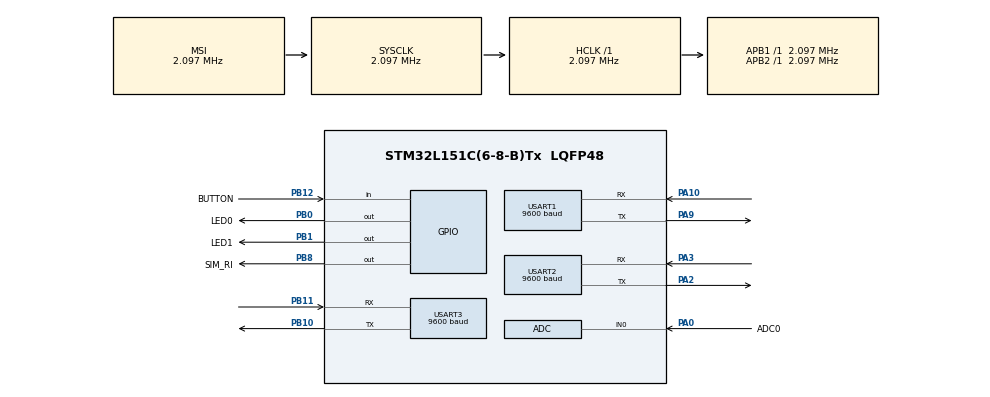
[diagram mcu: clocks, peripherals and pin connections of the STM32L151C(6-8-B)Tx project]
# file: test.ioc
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ADC.Channel-0\#ChannelRegularConversion=ADC_CHANNEL_0
ADC.NbrOfConversionFlag=1
ADC.Rank-0\#ChannelRegularConversion=1
ADC.SamplingTime-0\#ChannelRegularConversion=ADC_SAMPLETIME_4CYCLES
Mcu.Family=STM32L1
Mcu.Name=STM32L151C(6-8-B)Tx
Mcu.Package=LQFP48
NVIC.PriorityGroup=NVIC_PRIORITYGROUP_4
PA0-WKUP1.GPIO_Label=ADC0
PA0-WKUP1.Mode=IN0
PA0-WKUP1.Signal=ADC_IN0
PA10.Mode=Asynchronous
PA10.Signal=USART1_RX
PA13.Mode=Serial_Wire
PA13.Signal=SYS_JTMS-SWDIO
PA14.Mode=Serial_Wire
PA14.Signal=SYS_JTCK-SWCLK
PA2.Mode=Asynchronous
PA2.Signal=USART2_TX
PA3.Mode=Asynchronous
PA3.Signal=USART2_RX
PA9.Mode=Asynchronous
PA9.Signal=USART1_TX
PB0.GPIO_Label=LED0
PB0.Signal=GPIO_Output
PB1.GPIO_Label=LED1
PB1.Signal=GPIO_Output
PB10.Mode=Asynchronous
PB10.Signal=USART3_TX
PB11.Mode=Asynchronous
PB11.Signal=USART3_RX
PB12.GPIO_Label=BUTTON
PB12.GPIO_PuPd=GPIO_PULLUP
PB12.Signal=GPIO_Input
PB8.GPIO_Label=SIM_RI
PB8.Signal=GPIO_Output
ProjectManager.HeapSize=0x200
ProjectManager.StackSize=0x400
ProjectManager.TargetToolchain=MDK-ARM V5.32
RCC.AHBFreq_Value=2097000
RCC.APB1Freq_Value=2097000
RCC.APB1TimFreq_Value=2097000
RCC.APB2Freq_Value=2097000
RCC.APB2TimFreq_Value=2097000
RCC.HCLKFreq_Value=2097000
RCC.HSE_VALUE=24000000
RCC.HSI_VALUE=16000000
RCC.LSE_VALUE=32768
RCC.MSI_VALUE=2097000
RCC.SYSCLKFreq_VALUE=2097000
RCC.VCOOutputFreq_Value=48000000
USART1.BaudRate=9600
USART1.VirtualMode=VM_ASYNC
USART2.BaudRate=9600
USART2.VirtualMode=VM_ASYNC
USART3.BaudRate=9600
USART3.VirtualMode=VM_ASYNC
board=custom

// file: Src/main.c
/* USER CODE BEGIN Header */
/**
  ******************************************************************************
  * @file           : main.c
  * @brief          : Main program body
  ******************************************************************************
  * @attention
  *
  * Copyright (c) 2023 STMicroelectronics.
  * All rights reserved.
  *
  * This software is licensed under terms that can be found in the LICENSE file
  * in the root directory of this software component.
  * If no LICENSE file comes with this software, it is provided AS-IS.
  *
  ******************************************************************************
  */
/* USER CODE END Header */
#include "main.h"

ADC_HandleTypeDef hadc;

UART_HandleTypeDef huart1;
UART_HandleTypeDef huart2;
UART_HandleTypeDef huart3;

void SystemClock_Config(void);
static void MX_GPIO_Init(void);
static void MX_ADC_Init(void);
static void MX_USART1_UART_Init(void);
static void MX_USART2_UART_Init(void);
static void MX_USART3_UART_Init(void);
/* USER CODE BEGIN PFP */

uint8_t uart1_buff[] = " **** this is to the RS232 **** ";
uint8_t uart2_buff[] = " **** this is to the Debug **** ";

/* USER CODE END PFP */

int main(void)
{

  /* MCU Configuration--------------------------------------------------------*/

  /* Reset of all peripherals, Initializes the Flash interface and the Systick. */
  HAL_Init();

  /* Configure the system clock */
  SystemClock_Config();

  /* Initialize all configured peripherals */
  MX_GPIO_Init();
  MX_ADC_Init();
  MX_USART1_UART_Init();
  MX_USART2_UART_Init();
  MX_USART3_UART_Init();

  /* Infinite loop */
  while (1)
  {

    /* USER CODE BEGIN 3 */

		HAL_GPIO_TogglePin(GPIOB, LED0_Pin); // ��תLED
		HAL_Delay(200);
		HAL_GPIO_TogglePin(GPIOB, LED1_Pin); // ��תLED
		HAL_Delay(200);
		HAL_UART_Transmit(&huart2, (uint8_t*)uart1_buff, uart1_buffsize, 5000);
		HAL_Delay(200);
		HAL_UART_Transmit(&huart2, (uint8_t*)uart2_buff, uart2_buffsize, 5000);
		HAL_Delay(200);

		//HAL_GPIO_WritePin(GPIOB, LED0_Pin|LED1_Pin, GPIO_PIN_RESET);
		//HAL_Delay(500);

		//HAL_GPIO_WritePin(GPIOB, LED0_Pin|LED1_Pin, GPIO_PIN_SET);
		//HAL_Delay(500);

  }
  /* USER CODE END 3 */
}

void SystemClock_Config(void)
{
  RCC_OscInitTypeDef RCC_OscInitStruct = {0};
  RCC_ClkInitTypeDef RCC_ClkInitStruct = {0};

  /** Configure the main internal regulator output voltage
  */
  __HAL_PWR_VOLTAGESCALING_CONFIG(PWR_REGULATOR_VOLTAGE_SCALE1);

  /** Initializes the RCC Oscillators according to the specified parameters
  * in the RCC_OscInitTypeDef structure.
  */
  RCC_OscInitStruct.OscillatorType = RCC_OSCILLATORTYPE_HSI|RCC_OSCILLATORTYPE_MSI;
  RCC_OscInitStruct.HSIState = RCC_HSI_ON;
  RCC_OscInitStruct.HSICalibrationValue = RCC_HSICALIBRATION_DEFAULT;
  RCC_OscInitStruct.MSIState = RCC_MSI_ON;
  RCC_OscInitStruct.MSICalibrationValue = 0;
  RCC_OscInitStruct.MSIClockRange = RCC_MSIRANGE_5;
  RCC_OscInitStruct.PLL.PLLState = RCC_PLL_NONE;
  if (HAL_RCC_OscConfig(&RCC_OscInitStruct) != HAL_OK)
  {
    Error_Handler();
  }

  /** Initializes the CPU, AHB and APB buses clocks
  */
  RCC_ClkInitStruct.ClockType = RCC_CLOCKTYPE_HCLK|RCC_CLOCKTYPE_SYSCLK
                              |RCC_CLOCKTYPE_PCLK1|RCC_CLOCKTYPE_PCLK2;
  RCC_ClkInitStruct.SYSCLKSource = RCC_SYSCLKSOURCE_MSI;
  RCC_ClkInitStruct.AHBCLKDivider = RCC_SYSCLK_DIV1;
  RCC_ClkInitStruct.APB1CLKDivider = RCC_HCLK_DIV1;
  RCC_ClkInitStruct.APB2CLKDivider = RCC_HCLK_DIV1;

  if (HAL_RCC_ClockConfig(&RCC_ClkInitStruct, FLASH_LATENCY_0) != HAL_OK)
  {
    Error_Handler();
  }
}

static void MX_ADC_Init(void)
{

  ADC_ChannelConfTypeDef sConfig = {0};

  /** Configure the global features of the ADC (Clock, Resolution, Data Alignment and number of conversion)
  */
  hadc.Instance = ADC1;
  hadc.Init.ClockPrescaler = ADC_CLOCK_ASYNC_DIV1;
  hadc.Init.Resolution = ADC_RESOLUTION_12B;
  hadc.Init.DataAlign = ADC_DATAALIGN_RIGHT;
  hadc.Init.ScanConvMode = ADC_SCAN_DISABLE;
  hadc.Init.EOCSelection = ADC_EOC_SEQ_CONV;
  hadc.Init.LowPowerAutoWait = ADC_AUTOWAIT_DISABLE;
  hadc.Init.LowPowerAutoPowerOff = ADC_AUTOPOWEROFF_DISABLE;
  hadc.Init.ChannelsBank = ADC_CHANNELS_BANK_A;
  hadc.Init.ContinuousConvMode = DISABLE;
  hadc.Init.NbrOfConversion = 1;
  hadc.Init.DiscontinuousConvMode = DISABLE;
  hadc.Init.ExternalTrigConv = ADC_SOFTWARE_START;
  hadc.Init.ExternalTrigConvEdge = ADC_EXTERNALTRIGCONVEDGE_NONE;
  hadc.Init.DMAContinuousRequests = DISABLE;
  if (HAL_ADC_Init(&hadc) != HAL_OK)
  {
    Error_Handler();
  }

  /** Configure for the selected ADC regular channel its corresponding rank in the sequencer and its sample time.
  */
  sConfig.Channel = ADC_CHANNEL_0;
  sConfig.Rank = ADC_REGULAR_RANK_1;
  sConfig.SamplingTime = ADC_SAMPLETIME_4CYCLES;
  if (HAL_ADC_ConfigChannel(&hadc, &sConfig) != HAL_OK)
  {
    Error_Handler();
  }

}

static void MX_USART1_UART_Init(void)
{

  huart1.Instance = USART1;
  huart1.Init.BaudRate = 9600;
  huart1.Init.WordLength = UART_WORDLENGTH_8B;
  huart1.Init.StopBits = UART_STOPBITS_1;
  huart1.Init.Parity = UART_PARITY_NONE;
  huart1.Init.Mode = UART_MODE_TX_RX;
  huart1.Init.HwFlowCtl = UART_HWCONTROL_NONE;
  huart1.Init.OverSampling = UART_OVERSAMPLING_16;
  if (HAL_UART_Init(&huart1) != HAL_OK)
  {
    Error_Handler();
  }

}

static void MX_USART2_UART_Init(void)
{

  huart2.Instance = USART2;
  huart2.Init.BaudRate = 9600;
  huart2.Init.WordLength = UART_WORDLENGTH_8B;
  huart2.Init.StopBits = UART_STOPBITS_1;
  huart2.Init.Parity = UART_PARITY_NONE;
  huart2.Init.Mode = UART_MODE_TX_RX;
  huart2.Init.HwFlowCtl = UART_HWCONTROL_NONE;
  huart2.Init.OverSampling = UART_OVERSAMPLING_16;
  if (HAL_UART_Init(&huart2) != HAL_OK)
  {
    Error_Handler();
  }

}

static void MX_USART3_UART_Init(void)
{

  huart3.Instance = USART3;
  huart3.Init.BaudRate = 9600;
  huart3.Init.WordLength = UART_WORDLENGTH_8B;
  huart3.Init.StopBits = UART_STOPBITS_1;
  huart3.Init.Parity = UART_PARITY_NONE;
  huart3.Init.Mode = UART_MODE_TX_RX;
  huart3.Init.HwFlowCtl = UART_HWCONTROL_NONE;
  huart3.Init.OverSampling = UART_OVERSAMPLING_16;
  if (HAL_UART_Init(&huart3) != HAL_OK)
  {
    Error_Handler();
  }

}

static void MX_GPIO_Init(void)
{
  GPIO_InitTypeDef GPIO_InitStruct = {0};

  /* GPIO Ports Clock Enable */
  __HAL_RCC_GPIOA_CLK_ENABLE();
  __HAL_RCC_GPIOB_CLK_ENABLE();

  /*Configure GPIO pin Output Level */
  HAL_GPIO_WritePin(GPIOB, LED0_Pin|SIM_RI_Pin, GPIO_PIN_RESET);
	HAL_GPIO_WritePin(GPIOB, LED1_Pin, GPIO_PIN_SET);

  /*Configure GPIO pins : LED0_Pin LED1_Pin SIM_RI_Pin */
  GPIO_InitStruct.Pin = LED0_Pin|LED1_Pin|SIM_RI_Pin;
  GPIO_InitStruct.Mode = GPIO_MODE_OUTPUT_PP;
  GPIO_InitStruct.Pull = GPIO_NOPULL;
  GPIO_InitStruct.Speed = GPIO_SPEED_FREQ_LOW;
  HAL_GPIO_Init(GPIOB, &GPIO_InitStruct);

  /*Configure GPIO pin : BUTTON_Pin */
  GPIO_InitStruct.Pin = BUTTON_Pin;
  GPIO_InitStruct.Mode = GPIO_MODE_INPUT;
  GPIO_InitStruct.Pull = GPIO_PULLUP;
  HAL_GPIO_Init(BUTTON_GPIO_Port, &GPIO_InitStruct);

}

void Error_Handler(void)
{
  __disable_irq();
  while (1)
  {
  }
}
